VERSION "created by canmatrix"

NS_ :

BS_:

BU_: User ADM_PC_LL25 ADM_PC_BC25 ADM_PC_BP25 ADM_PC_BI25

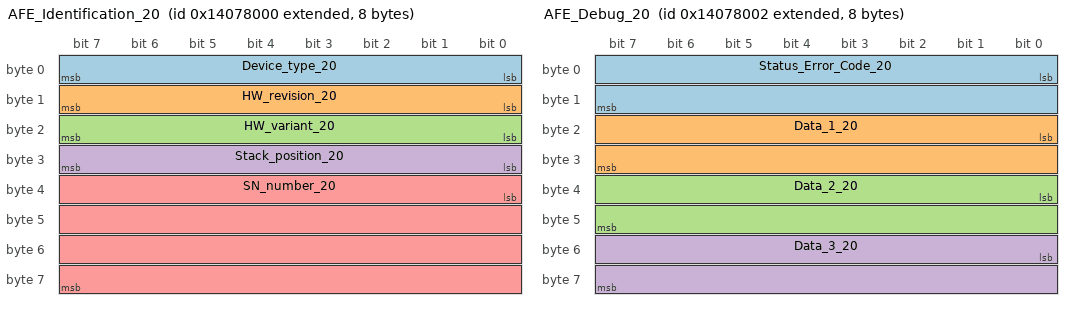
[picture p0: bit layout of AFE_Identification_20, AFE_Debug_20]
BO_ 2483519488 AFE_Identification_20: 8 ADM_PC_BP25
 SG_ Device_type_20 : 0|8@1+ (1,0) [0|255] "" Vector__XXX
 SG_ HW_revision_20 : 8|8@1+ (1,0) [0|255] "" Vector__XXX
 SG_ HW_variant_20 : 16|8@1+ (1,0) [0|255] "" Vector__XXX
 SG_ Stack_position_20 : 24|8@1+ (1,0) [0|255] "" Vector__XXX
 SG_ SN_number_20 : 32|32@1+ (1,0) [0|4294967295] "" Vector__XXX

BO_ 2483519489 AFE_FwInfo_20: 8 ADM_PC_BP25
 SG_ FW_info_mux_20 M : 56|8@1+ (1,0) [0|255] "" Vector__XXX
 SG_ FW_revision_0_20 m0 : 0|8@1+ (1,0) [0|255] "" Vector__XXX
 SG_ FW_revision_1_20 m0 : 8|8@1+ (1,0) [0|255] "" Vector__XXX
 SG_ FW_revision_2_20 m0 : 16|8@1+ (1,0) [0|255] "" Vector__XXX
 SG_ FW_revision_3_20 m0 : 24|8@1+ (1,0) [0|255] "" Vector__XXX
 SG_ FW_revision_4_20 m0 : 32|8@1+ (1,0) [0|255] "" Vector__XXX
 SG_ FW_revision_5_20 m0 : 40|8@1+ (1,0) [0|255] "" Vector__XXX
 SG_ FW_revision_6_20 m0 : 48|8@1+ (1,0) [0|255] "" Vector__XXX
 SG_ FW_revision_7_20 m1 : 0|8@1+ (1,0) [0|255] "" Vector__XXX
 SG_ FW_revision_8_20 m1 : 8|8@1+ (1,0) [0|255] "" Vector__XXX
 SG_ FW_revision_9_20 m1 : 16|8@1+ (1,0) [0|255] "" Vector__XXX
 SG_ FW_revision_10_20 m1 : 24|8@1+ (1,0) [0|255] "" Vector__XXX
 SG_ FW_revision_11_20 m1 : 32|8@1+ (1,0) [0|255] "" Vector__XXX
 SG_ FW_revision_12_20 m1 : 40|8@1+ (1,0) [0|255] "" Vector__XXX
 SG_ FW_revision_13_20 m1 : 48|8@1+ (1,0) [0|255] "" Vector__XXX
 SG_ FW_datecode_0_20 m2 : 0|8@1+ (1,0) [0|255] "" Vector__XXX
 SG_ FW_datecode_1_20 m2 : 8|8@1+ (1,0) [0|255] "" Vector__XXX
 SG_ FW_datecode_2_20 m2 : 16|8@1+ (1,0) [0|255] "" Vector__XXX
 SG_ FW_datecode_3_20 m2 : 24|8@1+ (1,0) [0|255] "" Vector__XXX
 SG_ FW_datecode_4_20 m2 : 32|8@1+ (1,0) [0|255] "" Vector__XXX
 SG_ FW_datecode_5_20 m2 : 40|8@1+ (1,0) [0|255] "" Vector__XXX
 SG_ FW_datecode_6_20 m2 : 48|8@1+ (1,0) [0|255] "" Vector__XXX
 SG_ FW_datecode_7_20 m3 : 0|8@1+ (1,0) [0|255] "" Vector__XXX
 SG_ FW_datecode_8_20 m3 : 8|8@1+ (1,0) [0|255] "" Vector__XXX
 SG_ FW_datecode_9_20 m3 : 16|8@1+ (1,0) [0|255] "" Vector__XXX
 SG_ FW_datecode_10_20 m3 : 24|8@1+ (1,0) [0|255] "" Vector__XXX
 SG_ FW_datecode_11_20 m3 : 32|8@1+ (1,0) [0|255] "" Vector__XXX
 SG_ FW_datecode_12_20 m3 : 40|8@1+ (1,0) [0|255] "" Vector__XXX
 SG_ FW_datecode_13_20 m3 : 48|8@1+ (1,0) [0|255] "" Vector__XXX

BO_ 2483519501 _AFE_Boot_FwInfo_20: 8 ADM_PC_BP25
 SG_ Boot_FW_info_mux_20 M : 56|8@1+ (1,0) [0|255] "" Vector__XXX
 SG_ FW_revision_0_20 m0 : 0|8@1+ (1,0) [0|255] "" Vector__XXX
 SG_ FW_revision_1_20 m0 : 8|8@1+ (1,0) [0|255] "" Vector__XXX
 SG_ FW_revision_2_20 m0 : 16|8@1+ (1,0) [0|255] "" Vector__XXX
 SG_ FW_revision_3_20 m0 : 24|8@1+ (1,0) [0|255] "" Vector__XXX
 SG_ FW_revision_4_20 m0 : 32|8@1+ (1,0) [0|255] "" Vector__XXX
 SG_ FW_revision_5_20 m0 : 40|8@1+ (1,0) [0|255] "" Vector__XXX
 SG_ FW_revision_6_20 m0 : 48|8@1+ (1,0) [0|255] "" Vector__XXX
 SG_ FW_revision_7_20 m1 : 0|8@1+ (1,0) [0|255] "" Vector__XXX
 SG_ FW_revision_8_20 m1 : 8|8@1+ (1,0) [0|255] "" Vector__XXX
 SG_ FW_revision_9_20 m1 : 16|8@1+ (1,0) [0|255] "" Vector__XXX
 SG_ FW_revision_10_20 m1 : 24|8@1+ (1,0) [0|255] "" Vector__XXX
 SG_ FW_revision_11_20 m1 : 32|8@1+ (1,0) [0|255] "" Vector__XXX
 SG_ FW_revision_12_20 m1 : 40|8@1+ (1,0) [0|255] "" Vector__XXX
 SG_ FW_revision_13_20 m1 : 48|8@1+ (1,0) [0|255] "" Vector__XXX
 SG_ FW_datecode_0_20 m2 : 0|8@1+ (1,0) [0|255] "" Vector__XXX
 SG_ FW_datecode_1_20 m2 : 8|8@1+ (1,0) [0|255] "" Vector__XXX
 SG_ FW_datecode_2_20 m2 : 16|8@1+ (1,0) [0|255] "" Vector__XXX
 SG_ FW_datecode_3_20 m2 : 24|8@1+ (1,0) [0|255] "" Vector__XXX
 SG_ FW_datecode_4_20 m2 : 32|8@1+ (1,0) [0|255] "" Vector__XXX
 SG_ FW_datecode_5_20 m2 : 40|8@1+ (1,0) [0|255] "" Vector__XXX
 SG_ FW_datecode_6_20 m2 : 48|8@1+ (1,0) [0|255] "" Vector__XXX
 SG_ FW_datecode_7_20 m3 : 0|8@1+ (1,0) [0|255] "" Vector__XXX
 SG_ FW_datecode_8_20 m3 : 8|8@1+ (1,0) [0|255] "" Vector__XXX
 SG_ FW_datecode_9_20 m3 : 16|8@1+ (1,0) [0|255] "" Vector__XXX
 SG_ FW_datecode_10_20 m3 : 24|8@1+ (1,0) [0|255] "" Vector__XXX
 SG_ FW_datecode_11_20 m3 : 32|8@1+ (1,0) [0|255] "" Vector__XXX
 SG_ FW_datecode_12_20 m3 : 40|8@1+ (1,0) [0|255] "" Vector__XXX
 SG_ FW_datecode_13_20 m3 : 48|8@1+ (1,0) [0|255] "" Vector__XXX

BO_ 2483519490 AFE_Debug_20: 8 ADM_PC_BP25
 SG_ Status_Error_Code_20 : 0|16@1+ (1,0) [0|65535] "" Vector__XXX
 SG_ Data_1_20 : 16|16@1+ (1,0) [0|65535] "" Vector__XXX
 SG_ Data_2_20 : 32|16@1+ (1,0) [0|65535] "" Vector__XXX
 SG_ Data_3_20 : 48|16@1+ (1,0) [0|65535] "" Vector__XXX

BO_ 2483519495 AFE_Status_20: 8 ADM_PC_BP25
 SG_ Running_20 : 0|1@1+ (1,0) [0|1] "" Vector__XXX
 SG_ PWM_20 : 1|1@1+ (1,0) [0|1] "" Vector__XXX
 SG_ Current_dc_loop_mode_20 : 2|1@1+ (1,0) [0|1] "" Vector__XXX
 SG_ Current_ac_loop_mode_20 : 3|1@1+ (1,0) [0|1] "" Vector__XXX
 SG_ Buck_20 : 5|1@1+ (1,0) [0|1] "" Vector__XXX
 SG_ Boost_20 : 6|1@1+ (1,0) [0|1] "" Vector__XXX
 SG_ Precharge_dc_buck_mode_20 : 7|1@1+ (1,0) [0|1] "" Vector__XXX
 SG_ Precharge_dc_boost_mode_20 : 8|1@1+ (1,0) [0|1] "" Vector__XXX
 SG_ Rectifier_3ph_20 : 9|1@1+ (1,0) [0|1] "" Vector__XXX
 SG_ Stack_mode_20 : 10|1@1+ (1,0) [0|1] "" Vector__XXX
 SG_ Master_20 : 11|1@1+ (1,0) [0|1] "" Vector__XXX
 SG_ Slave_20 : 12|1@1+ (1,0) [0|1] "" Vector__XXX
 SG_ Inverter_1ph_20 : 13|1@1+ (1,0) [0|1] "" Vector__XXX
 SG_ Boost_Neutral_20 : 14|1@1+ (1,0) [0|1] "" Vector__XXX
 SG_ Rectifier_1ph_20 : 15|1@1+ (1,0) [0|1] "" Vector__XXX
 SG_ Inverter_3ph_20 : 16|1@1+ (1,0) [0|1] "" Vector__XXX
 SG_ Ready_20 : 17|1@1+ (1,0) [0|1] "" Vector__XXX
 SG_ Inverter_1ph_Sync_20 : 18|1@1+ (1,0) [0|1] "" Vector__XXX
 SG_ Neutral_20 : 19|1@1+ (1,0) [0|1] "" Vector__XXX
 SG_ Rectifier_1ph_Buck_20 : 20|1@1+ (1,0) [0|1] "" Vector__XXX
 SG_ Inverter_1ph_Boost_20 : 21|1@1+ (1,0) [0|1] "" Vector__XXX
 SG_ Rectifier_distributed_20 : 22|1@1+ (1,0) [0|1] "" Vector__XXX
 SG_ MPPT_buck_20 : 23|1@1+ (1,0) [0|1] "" Vector__XXX
 SG_ MPPT_boost_20 : 24|1@1+ (1,0) [0|1] "" Vector__XXX
 SG_ Buck_2p_float_20 : 25|1@1+ (1,0) [0|1] "" Vector__XXX
 SG_ Inverter_1ph_Distributed_20 : 26|1@1+ (1,0) [0|1] "" Vector__XXX

BO_ 2483519494 AFE_Faults_20: 3 ADM_PC_BP25
 SG_ Protection_trip_internal_20 : 0|1@1+ (1,0) [0|1] "" Vector__XXX
 SG_ Protection_trip_external_20 : 1|1@1+ (1,0) [0|1] "" Vector__XXX
 SG_ Phase_U_overcurrent_20 : 2|1@1+ (1,0) [0|1] "" Vector__XXX
 SG_ Phase_U_overvoltage_20 : 3|1@1+ (1,0) [0|1] "" Vector__XXX
 SG_ Phase_U_undervoltage_20 : 4|1@1+ (1,0) [0|1] "" Vector__XXX
 SG_ Phase_V_overvoltage_20 : 5|1@1+ (1,0) [0|1] "" Vector__XXX
 SG_ Phase_V_undervoltage_20 : 6|1@1+ (1,0) [0|1] "" Vector__XXX
 SG_ Phase_V_overcurrent_20 : 7|1@1+ (1,0) [0|1] "" Vector__XXX
 SG_ Phase_W_overvoltage_20 : 8|1@1+ (1,0) [0|1] "" Vector__XXX
 SG_ Phase_W_undervoltage_20 : 9|1@1+ (1,0) [0|1] "" Vector__XXX
 SG_ Phase_W_overcurrent_20 : 10|1@1+ (1,0) [0|1] "" Vector__XXX
 SG_ DC_undervoltage_20 : 11|1@1+ (1,0) [0|1] "" Vector__XXX
 SG_ DC_overvoltage_20 : 12|1@1+ (1,0) [0|1] "" Vector__XXX
 SG_ MOSFET_overtemperature_20 : 13|1@1+ (1,0) [0|1] "" Vector__XXX
 SG_ Inductor_overtemperature_20 : 14|1@1+ (1,0) [0|1] "" Vector__XXX
 SG_ Keep_Alive_not_served_20 : 15|1@1+ (1,0) [0|1] "" Vector__XXX
 SG_ PLL_not_locked_20 : 16|1@1+ (1,0) [0|1] "" Vector__XXX
 SG_ NFO_20 : 20|1@1+ (1,0) [0|1] "" Vector__XXX
 SG_ Measurement_system_failure_20 : 21|1@1+ (1,0) [0|1] "" Vector__XXX
 SG_ EEPROM_failure_20 : 22|1@1+ (1,0) [0|1] "" Vector__XXX
 SG_ System_20 : 23|1@1+ (1,0) [0|1] "" Vector__XXX

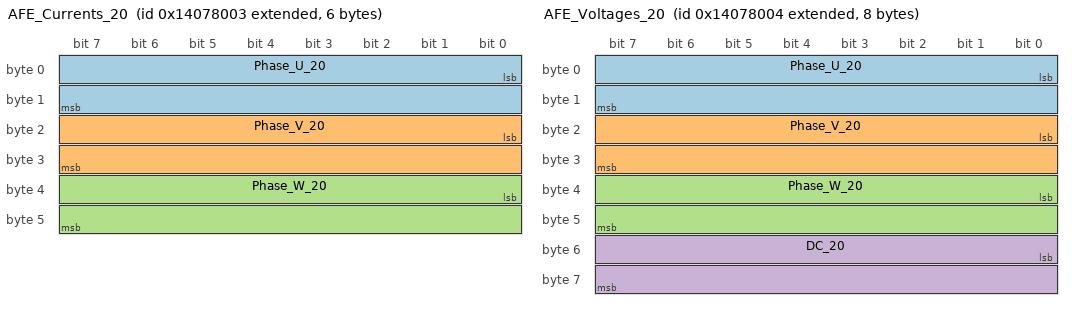
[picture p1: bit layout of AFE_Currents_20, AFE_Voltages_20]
BO_ 2483519491 AFE_Currents_20: 6 ADM_PC_BP25
 SG_ Phase_U_20 : 0|16@1- (0.01,0) [-327.68|327.67] "A" Vector__XXX
 SG_ Phase_V_20 : 16|16@1- (0.01,0) [-327.68|327.67] "A" Vector__XXX
 SG_ Phase_W_20 : 32|16@1- (0.01,0) [-327.68|327.67] "A" Vector__XXX

BO_ 2483519504 AFE_DC_Bus_current_20: 2 ADM_PC_BP25
 SG_ Bus_current_20 : 0|16@1- (0.01,0) [-327.68|327.67] "A" Vector__XXX

BO_ 2483519502 _AFE_Broadcast_20: 8 ADM_PC_BP25
 SG_ Diagnostics_Index_20 M : 56|8@1+ (1,0) [0|255] "" Vector__XXX
 SG_ Phase_U_20 m1 : 8|16@1- (0.01,0) [-327.68|327.67] "A" ADM_PC_BP25
 SG_ Phase_V_20 m1 : 24|16@1- (0.01,0) [-327.68|327.67] "A" ADM_PC_BP25
 SG_ Phase_W_20 m1 : 40|16@1- (0.01,0) [-327.68|327.67] "A" ADM_PC_BP25
 SG_ Stack_position_20 : 0|5@1+ (1,0) [0|31] "" ADM_PC_BP25
 SG_ Group_ID_20 : 5|3@1+ (1,0) [0|7] "" ADM_PC_BP25

BO_ 2483519492 AFE_Voltages_20: 8 ADM_PC_BP25
 SG_ Phase_U_20 : 0|16@1- (0.1,0) [-3276.8|3276.7] "V" Vector__XXX
 SG_ Phase_V_20 : 16|16@1- (0.1,0) [-3276.8|3276.7] "V" Vector__XXX
 SG_ Phase_W_20 : 32|16@1- (0.1,0) [-3276.8|3276.7] "V" Vector__XXX
 SG_ DC_20 : 48|16@1- (0.1,0) [-3276.8|3276.7] "V" Vector__XXX

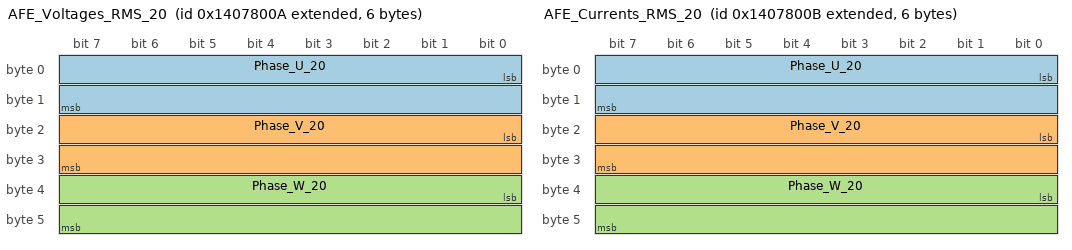
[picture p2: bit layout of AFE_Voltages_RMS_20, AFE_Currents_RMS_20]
BO_ 2483519498 AFE_Voltages_RMS_20: 6 ADM_PC_BP25
 SG_ Phase_U_20 : 0|16@1+ (0.1,0) [0|6553.5] "V" Vector__XXX
 SG_ Phase_V_20 : 16|16@1+ (0.1,0) [0|6553.5] "V" Vector__XXX
 SG_ Phase_W_20 : 32|16@1+ (0.1,0) [0|6553.5] "V" Vector__XXX

BO_ 2483519499 AFE_Currents_RMS_20: 6 ADM_PC_BP25
 SG_ Phase_U_20 : 0|16@1+ (0.01,0) [0.00|655.35] "A" Vector__XXX
 SG_ Phase_V_20 : 16|16@1+ (0.01,0) [0.00|655.35] "A" Vector__XXX
 SG_ Phase_W_20 : 32|16@1+ (0.01,0) [0.00|655.35] "A" Vector__XXX

BO_ 2483519500 AFE_Mains_20: 4 ADM_PC_BP25
 SG_ Frequency_20 : 0|16@1+ (0.01,0) [0.00|655.35] "Hz" Vector__XXX
 SG_ Phase_20 : 16|16@1- (0.1,0) [-3276.8|3276.7] "Deg." Vector__XXX

BO_ 2483519493 AFE_Temperatures_20: 4 ADM_PC_BP25
 SG_ Temp_Bridge_20 : 0|16@1- (0.01,0) [-327.68|327.67] "°C" Vector__XXX
 SG_ Temp_Inductors_20 : 16|16@1- (0.01,0) [-327.68|327.67] "°C" Vector__XXX

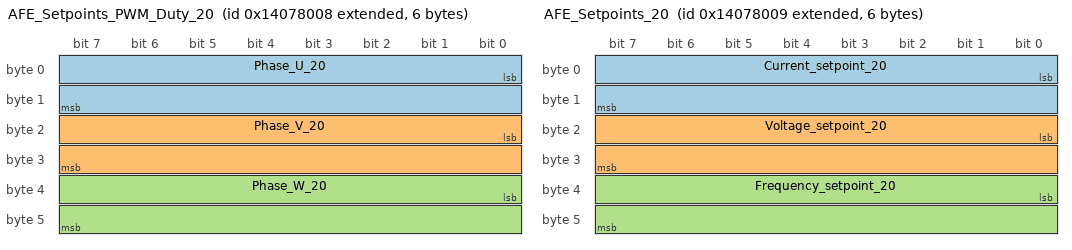
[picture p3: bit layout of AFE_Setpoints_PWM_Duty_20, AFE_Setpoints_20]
BO_ 2483519496 AFE_Setpoints_PWM_Duty_20: 6 ADM_PC_BP25
 SG_ Phase_U_20 : 0|16@1+ (0.001525902,0) [0E-009|99.999987570] "%" Vector__XXX
 SG_ Phase_V_20 : 16|16@1+ (0.001525902,0) [0E-009|99.999987570] "%" Vector__XXX
 SG_ Phase_W_20 : 32|16@1+ (0.001525902,0) [0E-009|99.999987570] "%" Vector__XXX

BO_ 2483519497 AFE_Setpoints_20: 6 ADM_PC_BP25
 SG_ Current_setpoint_20 : 0|16@1- (0.01,0) [-327.68|327.67] "A" Vector__XXX
 SG_ Voltage_setpoint_20 : 16|16@1+ (0.1,0) [0|6553.5] "V" Vector__XXX
 SG_ Frequency_setpoint_20 : 32|16@1+ (0.01,0) [0.00|655.35] "Hz" Vector__XXX

BO_ 2483486816 AFE_Keep_Alive_20: 1 User
 SG_ Keep_Alive_Enable_20 : 0|1@1+ (1,0) [0|1] "" ADM_PC_BP25

BO_ 2483486784 AFE_Mode_Control_20: 8 User
 SG_ Converter_ON_20 : 0|1@1+ (1,0) [0|1] "" ADM_PC_BP25
 SG_ PWM_ON_20 : 1|1@1+ (1,0) [0|1] "" ADM_PC_BP25
 SG_ DC_Current_feedback_ON_20 : 2|1@1+ (1,0) [0|1] "" ADM_PC_BP25
 SG_ AC_Current_feedback_ON_20 : 3|1@1+ (1,0) [0|1] "" ADM_PC_BP25
 SG_ Buck_ON_20 : 5|1@1+ (1,0) [0|1] "" ADM_PC_BP25
 SG_ Boost_ON_20 : 6|1@1+ (1,0) [0|1] "" ADM_PC_BP25
 SG_ Rectifier_3ph_ON_20 : 9|1@1+ (1,0) [0|1] "" ADM_PC_BP25
 SG_ Inverter_1ph_ON_20 : 10|1@1+ (1,0) [0|1] "" ADM_PC_BP25
 SG_ Rectifier_1ph_ON_20 : 11|1@1+ (1,0) [0|1] "" ADM_PC_BP25
 SG_ Boost_Neutral_ON_20 : 12|1@1+ (1,0) [0|1] "" ADM_PC_BP25
 SG_ Inverter_3ph_ON_20 : 13|1@1+ (1,0) [0|1] "" ADM_PC_BP25
 SG_ Inverter_1ph_Sync_ON_20 : 14|1@1+ (1,0) [0|1] "" ADM_PC_BP25
 SG_ Neutral_ON_20 : 15|1@1+ (1,0) [0|1] "" ADM_PC_BP25
 SG_ Rectifier_1ph_Buck_ON_20 : 16|1@1+ (1,0) [0|1] "" ADM_PC_BP25
 SG_ Inverter_1ph_Boost_ON_20 : 17|1@1+ (1,0) [0|1] "" ADM_PC_BP25
 SG_ Rectifier_Distributed_ON_20 : 18|1@1+ (1,0) [0|1] "" ADM_PC_BP25
 SG_ MPPT_buck_ON_20 : 19|1@1+ (1,0) [0|1] "" ADM_PC_BP25
 SG_ MPPT_boost_ON_20 : 20|1@1+ (1,0) [0|1] "" ADM_PC_BP25
 SG_ Buck_2p_float_ON_20 : 21|1@1+ (1,0) [0|1] "" ADM_PC_BP25
 SG_ Inverter_1ph_Distributed_ON_20 : 22|1@1+ (1,0) [0|1] "" ADM_PC_BP25

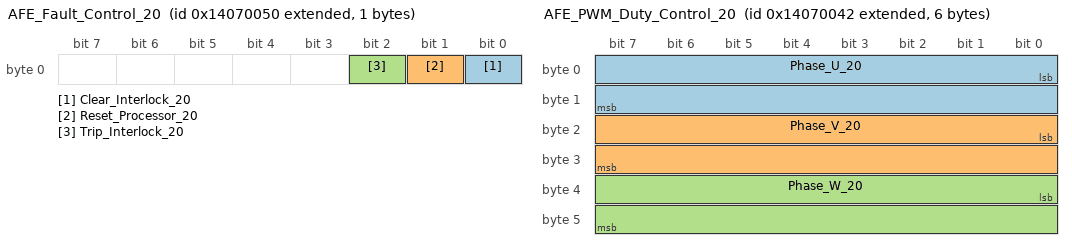
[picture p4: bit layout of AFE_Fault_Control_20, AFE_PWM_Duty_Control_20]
BO_ 2483486800 AFE_Fault_Control_20: 1 User
 SG_ Clear_Interlock_20 : 0|1@1+ (1,0) [0|1] "" ADM_PC_BP25
 SG_ Reset_Processor_20 : 1|1@1+ (1,0) [0|1] "" ADM_PC_BP25
 SG_ Trip_Interlock_20 : 2|1@1+ (1,0) [0|1] "" ADM_PC_BP25

BO_ 2483486785 AFE_Reactive_Current_Setpoint_Co: 2 User
 SG_ Reactive_current_setpoint_20 : 0|16@1- (0.01,0) [-150|150] "A" ADM_PC_BP25

BO_ 2483486786 AFE_PWM_Duty_Control_20: 6 User
 SG_ Phase_U_20 : 0|16@1+ (0.001525902,0) [0E-009|99.999987570] "%" ADM_PC_BP25
 SG_ Phase_V_20 : 16|16@1+ (0.001525902,0) [0E-009|99.999987570] "%" ADM_PC_BP25
 SG_ Phase_W_20 : 32|16@1+ (0.001525902,0) [0E-009|99.999987570] "%" ADM_PC_BP25

BO_ 2483486787 AFE_Current_Setpoint_Control_20: 2 User
 SG_ Current_setpoint_20 : 0|16@1- (0.01,0) [-150|150] "A" ADM_PC_BP25

BO_ 2483486788 AFE_Voltage_Setpoint_Control_20: 2 User
 SG_ Voltage_setpoint_20 : 0|16@1+ (0.1,0) [0|1500] "V" ADM_PC_BP25

BO_ 2483486792 AFE_Frequency_Setpoint_Control_2: 2 User
 SG_ Frequency_setpoint_20 : 0|16@1+ (0.01,0) [40|70] "Hz" ADM_PC_BP25

BO_ 2483486793 AFE_Phase_Setpoint_Control_20: 2 User
 SG_ Phase_setpoint_20 : 0|16@1+ (1,0) [0|360] "deg" ADM_PC_BP25

BO_ 2483486832 AFE_Rectifier_Setpoint_Control_2: 8 User
 SG_ Voltage_setpoint_2_20 : 0|16@1+ (0.1,0) [0|1500] "V" ADM_PC_BP25
 SG_ Current_setpoint_2_20 : 16|16@1- (0.01,0) [-150|150] "A" ADM_PC_BP25

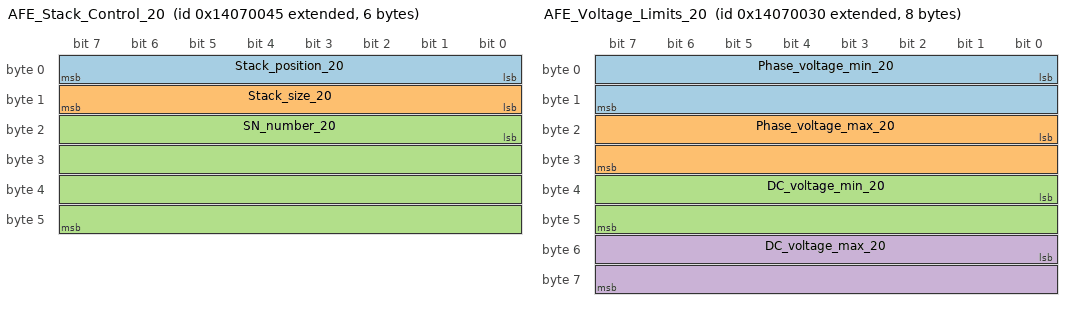
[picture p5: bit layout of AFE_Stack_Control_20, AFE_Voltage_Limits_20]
BO_ 2483486789 AFE_Stack_Control_20: 6 User
 SG_ Stack_position_20 : 0|8@1+ (1,0) [0|255] "" ADM_PC_BP25
 SG_ Stack_size_20 : 8|8@1+ (1,0) [0|255] "" ADM_PC_BP25
 SG_ SN_number_20 : 16|32@1+ (1,0) [0|4294967295] "" ADM_PC_BP25

BO_ 2483486768 AFE_Voltage_Limits_20: 8 User
 SG_ Phase_voltage_min_20 : 0|16@1- (0.1,0) [0|3276.7] "V" ADM_PC_BP25
 SG_ Phase_voltage_max_20 : 16|16@1- (0.1,0) [-3276.8|850] "V" ADM_PC_BP25
 SG_ DC_voltage_min_20 : 32|16@1- (0.1,0) [0|3276.7] "V" ADM_PC_BP25
 SG_ DC_voltage_max_20 : 48|16@1- (0.1,0) [-3276.8|850] "V" ADM_PC_BP25

BO_ 2483486769 AFE_Current_Limits_20: 4 User
 SG_ Phase_current_min_20 : 0|16@1- (0.01,0) [-60|60] "A" ADM_PC_BP25
 SG_ Phase_current_max_20 : 16|16@1- (0.01,0) [-60|60] "A" ADM_PC_BP25

BO_ 2483486796 AFE_Group_Control_20: 1 User
 SG_ Group_ID_20 : 0|8@1+ (1,0) [0|255] "" ADM_PC_BP25

BO_ 2483519503 AFE_Group_Info_20: 1 ADM_PC_BP25
 SG_ Group_ID_20 : 0|8@1+ (1,0) [0|255] "" Vector__XXX

BO_ 2483486817 AFE_System_Flags_Control_20: 8 User
 SG_ Factory_mode_20 : 0|1@1+ (1,0) [0|1] "" ADM_PC_BP25
 SG_ Silent_CAN_mode_20 : 1|1@1+ (1,0) [0|1] "" ADM_PC_BP25

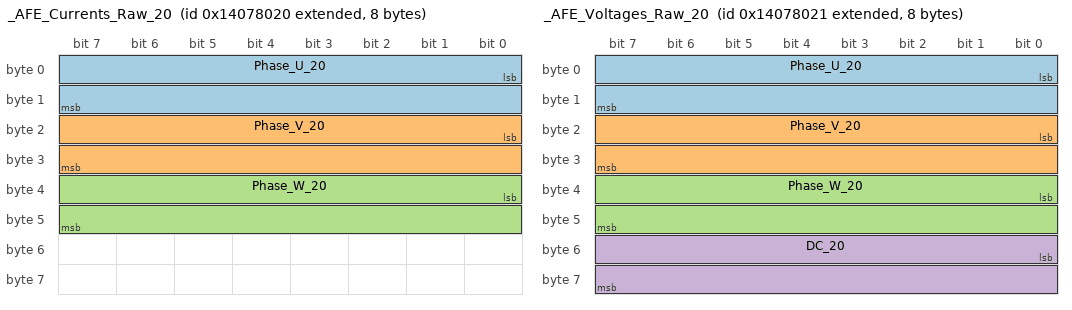
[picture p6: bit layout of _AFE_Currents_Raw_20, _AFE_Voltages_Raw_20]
BO_ 2483519520 _AFE_Currents_Raw_20: 8 ADM_PC_BP25
 SG_ Phase_U_20 : 0|16@1- (1,0) [-32768|32767] "" Vector__XXX
 SG_ Phase_V_20 : 16|16@1- (1,0) [-32768|32767] "" Vector__XXX
 SG_ Phase_W_20 : 32|16@1- (1,0) [-32768|32767] "" Vector__XXX

BO_ 2483519521 _AFE_Voltages_Raw_20: 8 ADM_PC_BP25
 SG_ Phase_U_20 : 0|16@1- (1,0) [-32768|32767] "" Vector__XXX
 SG_ Phase_V_20 : 16|16@1- (1,0) [-32768|32767] "" Vector__XXX
 SG_ Phase_W_20 : 32|16@1- (1,0) [-32768|32767] "" Vector__XXX
 SG_ DC_20 : 48|16@1- (1,0) [-32768|32767] "" Vector__XXX

BO_ 2483486794 _AFE_ADC_Calibration_Mode_20: 1 User
 SG_ Calibration_Index_20 M : 2|5@1+ (1,0) [0|31] "" Vector__XXX
 SG_ Current_U_20 m1 : 0|2@1+ (1,0) [0|3] "" ADM_PC_BP25
 SG_ Current_V_20 m2 : 0|2@1+ (1,0) [0|3] "" ADM_PC_BP25
 SG_ Current_W_20 m3 : 0|2@1+ (1,0) [0|3] "" ADM_PC_BP25
 SG_ Voltage_U_20 m4 : 0|2@1+ (1,0) [0|3] "" ADM_PC_BP25
 SG_ Voltage_V_20 m5 : 0|2@1+ (1,0) [0|3] "" ADM_PC_BP25
 SG_ Voltage_W_20 m6 : 0|2@1+ (1,0) [0|3] "" ADM_PC_BP25
 SG_ Voltage_DC_20 m7 : 0|2@1+ (1,0) [0|3] "" ADM_PC_BP25
 SG_ start_20 : 7|1@1+ (1,0) [0|1] "" ADM_PC_BP25

BO_ 2483486795 _AFE_ADC_Calibration_Setpoint_20: 3 User
 SG_ Calibration_Index_20 M : 16|5@1+ (1,0) [0|31] "" Vector__XXX
 SG_ Current_U_20 m1 : 0|16@1- (0.01,0) [-100|100] "A" ADM_PC_BP25
 SG_ Current_V_20 m2 : 0|16@1- (0.01,0) [-100|100] "A" ADM_PC_BP25
 SG_ Current_W_20 m3 : 0|16@1- (0.01,0) [-100|100] "A" ADM_PC_BP25
 SG_ Voltage_U_20 m4 : 0|16@1+ (0.1,0) [0|1500] "V" ADM_PC_BP25
 SG_ Voltage_V_20 m5 : 0|16@1+ (0.1,0) [0|1500] "V" ADM_PC_BP25
 SG_ Voltage_W_20 m6 : 0|16@1+ (0.1,0) [0|1500] "V" ADM_PC_BP25
 SG_ Voltage_DC_20 m7 : 0|16@1+ (0.1,0) [0|1500] "V" ADM_PC_BP25
 SG_ point_20 : 21|3@1+ (1,0) [0|7] "" ADM_PC_BP25

BO_ 2483486790 _AFE_Calibration_Offset_Update_2: 6 User
 SG_ Calibration_Index_20 M : 16|16@1+ (1,0) [0|65535] "" Vector__XXX
 SG_ Current_U_20 m0 : 0|16@1- (1,0) [-32768|32767] "ADC Counts" ADM_PC_BP25
 SG_ Current_V_20 m1 : 0|16@1- (1,0) [-32768|32767] "ADC Counts" ADM_PC_BP25
 SG_ Current_W_20 m2 : 0|16@1- (1,0) [-32768|32767] "ADC Counts" ADM_PC_BP25
 SG_ Voltage_U_20 m3 : 0|16@1- (1,0) [-32768|32767] "ADC Counts" ADM_PC_BP25
 SG_ Voltage_V_20 m4 : 0|16@1- (1,0) [-32768|32767] "ADC Counts" ADM_PC_BP25
 SG_ Voltage_W_20 m5 : 0|16@1- (1,0) [-32768|32767] "ADC Counts" ADM_PC_BP25
 SG_ Voltage_DC_20 m6 : 0|16@1- (1,0) [-32768|32767] "ADC Counts" ADM_PC_BP25
 SG_ CRC_20 : 32|16@1+ (1,0) [0|65535] "-" ADM_PC_BP25

BO_ 2483486791 _AFE_Calibration_Scale_Update_20: 6 User
 SG_ Calibration_Index_20 M : 16|16@1+ (1,0) [0|65535] "" Vector__XXX
 SG_ Current_U_20 m0 : 0|16@1- (0.0000152587890625,0) [-0.5000000000000000|0.4999847412109375] "scale = 1.0 + value" ADM_PC_BP25
 SG_ Current_V_20 m1 : 0|16@1- (0.0000152587890625,0) [-0.5000000000000000|0.4999847412109375] "scale = 1.0 + value" ADM_PC_BP25
 SG_ Current_W_20 m2 : 0|16@1- (0.0000152587890625,0) [-0.5000000000000000|0.4999847412109375] "scale = 1.0 + value" ADM_PC_BP25
 SG_ Voltage_U_20 m3 : 0|16@1- (0.0000152587890625,0) [-0.5000000000000000|0.4999847412109375] "scale = 1.0 + value" ADM_PC_BP25
 SG_ Voltage_V_20 m4 : 0|16@1- (0.0000152587890625,0) [-0.5000000000000000|0.4999847412109375] "scale = 1.0 + value" ADM_PC_BP25
 SG_ Voltage_W_20 m5 : 0|16@1- (0.0000152587890625,0) [-0.5000000000000000|0.4999847412109375] "scale = 1.0 + value" ADM_PC_BP25
 SG_ Voltage_DC_20 m6 : 0|16@1- (0.0000152587890625,0) [-0.5000000000000000|0.4999847412109375] "scale = 1.0 + value" ADM_PC_BP25
 SG_ CRC_20 : 32|16@1+ (1,0) [0|65535] "-" ADM_PC_BP25

BO_ 2483519569 _AFE_Calibration_Adc_Scale_20: 6 ADM_PC_BP25
 SG_ Adc_Index_20 M : 32|16@1+ (1,0) [0|65535] "" Vector__XXX
 SG_ Current_U_20 m0 : 0|32@1+ (1,0) [0|4294967295] "1 / adc_bins" User
 SG_ Current_V_20 m1 : 0|32@1+ (1,0) [0|4294967295] "1 / adc_bins" User
 SG_ Current_W_20 m2 : 0|32@1+ (1,0) [0|4294967295] "1 / adc_bins" User
 SG_ Voltage_U_20 m3 : 0|32@1+ (1,0) [0|4294967295] "1 / adc_bins" User
 SG_ Voltage_V_20 m4 : 0|32@1+ (1,0) [0|4294967295] "1 / adc_bins" User
 SG_ Voltage_W_20 m5 : 0|32@1+ (1,0) [0|4294967295] "1 / adc_bins" User
 SG_ Voltage_DC_20 m6 : 0|32@1+ (1,0) [0|4294967295] "1 / adc_bins" User

BO_ 2483519570 _AFE_Calibration_Adc_Fs_20: 6 ADM_PC_BP25
 SG_ Adc_Index_20 M : 32|16@1+ (1,0) [0|65535] "" Vector__XXX
 SG_ Current_U_20 m0 : 0|32@1+ (1,0) [0|4294967295] "Fullscale" User
 SG_ Current_V_20 m1 : 0|32@1+ (1,0) [0|4294967295] "Fullscale" User
 SG_ Current_W_20 m2 : 0|32@1+ (1,0) [0|4294967295] "Fullscale" User
 SG_ Voltage_U_20 m3 : 0|32@1+ (1,0) [0|4294967295] "Fullscale" User
 SG_ Voltage_V_20 m4 : 0|32@1+ (1,0) [0|4294967295] "Fullscale" User
 SG_ Voltage_W_20 m5 : 0|32@1+ (1,0) [0|4294967295] "Fullscale" User
 SG_ Voltage_DC_20 m6 : 0|32@1+ (1,0) [0|4294967295] "Fullscale" User

BO_ 2483519571 _AFE_Calibration_Adc_Offset_20: 4 ADM_PC_BP25
 SG_ Adc_Index_20 M : 16|16@1+ (1,0) [0|65535] "" Vector__XXX
 SG_ Current_U_20 m0 : 0|16@1- (1,0) [-32768|32767] "-" User
 SG_ Current_V_20 m1 : 0|16@1- (1,0) [-32768|32767] "-" User
 SG_ Current_W_20 m2 : 0|16@1- (1,0) [-32768|32767] "-" User
 SG_ Voltage_U_20 m3 : 0|16@1- (1,0) [-32768|32767] "-" User
 SG_ Voltage_V_20 m4 : 0|16@1- (1,0) [-32768|32767] "-" User
 SG_ Voltage_W_20 m5 : 0|16@1- (1,0) [-32768|32767] "-" User
 SG_ Voltage_DC_20 m6 : 0|16@1- (1,0) [-32768|32767] "-" User

BO_ 2483519572 _AFE_Calibration_Adc_Gain_20: 4 ADM_PC_BP25
 SG_ Adc_Index_20 M : 16|16@1+ (1,0) [0|65535] "" Vector__XXX
 SG_ Current_U_20 m0 : 0|16@1- (1,0) [-32768|32767] "-" User
 SG_ Current_V_20 m1 : 0|16@1- (1,0) [-32768|32767] "-" User
 SG_ Current_W_20 m2 : 0|16@1- (1,0) [-32768|32767] "-" User
 SG_ Voltage_U_20 m3 : 0|16@1- (1,0) [-32768|32767] "-" User
 SG_ Voltage_V_20 m4 : 0|16@1- (1,0) [-32768|32767] "-" User
 SG_ Voltage_W_20 m5 : 0|16@1- (1,0) [-32768|32767] "-" User
 SG_ Voltage_DC_20 m6 : 0|16@1- (1,0) [-32768|32767] "-" User

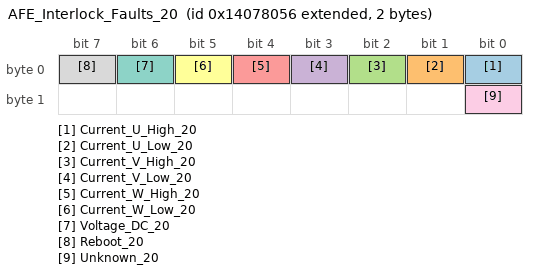
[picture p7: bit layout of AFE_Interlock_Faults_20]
BO_ 2483519574 AFE_Interlock_Faults_20: 2 ADM_PC_BP25
 SG_ Current_U_High_20 : 0|1@1+ (1,0) [0|1] "" Vector__XXX
 SG_ Current_U_Low_20 : 1|1@1+ (1,0) [0|1] "" Vector__XXX
 SG_ Current_V_High_20 : 2|1@1+ (1,0) [0|1] "" Vector__XXX
 SG_ Current_V_Low_20 : 3|1@1+ (1,0) [0|1] "" Vector__XXX
 SG_ Current_W_High_20 : 4|1@1+ (1,0) [0|1] "" Vector__XXX
 SG_ Current_W_Low_20 : 5|1@1+ (1,0) [0|1] "" Vector__XXX
 SG_ Voltage_DC_20 : 6|1@1+ (1,0) [0|1] "" Vector__XXX
 SG_ Reboot_20 : 7|1@1+ (1,0) [0|1] "" Vector__XXX
 SG_ Unknown_20 : 8|1@1+ (1,0) [0|1] "" Vector__XXX

BO_TX_BU_ 2483486784 : User,ADM_PC_LL25,ADM_PC_BC25,ADM_PC_BI25;
BO_TX_BU_ 2483486787 : User,ADM_PC_LL25,ADM_PC_BC25,ADM_PC_BI25;
BO_TX_BU_ 2483486788 : User,ADM_PC_LL25,ADM_PC_BC25,ADM_PC_BI25;
CM_ BO_ 2483519488  "Identification of the device";
CM_ BO_ 2483519489  "Git revision of the DSP firmware";
CM_ BO_ 2483519501  "Git revision of the bootloader firmware.";
CM_ BO_ 2483519490  "Values for debugging of HW/SW problems";
CM_ BO_ 2483519495  "Status bitfield";
CM_ BO_ 2483519494  "Fault bitfield";
CM_ BO_ 2483519491  "Current of phases U, V, W";
CM_ BO_ 2483519504  "Current of of the DC Bus";
CM_ BO_ 2483519502  "All AFEs will listen to this message";
CM_ BO_ 2483519499  "RMS Current of phases U, V, W";
CM_ BO_ 2483519500  "Three-Phase mains health (frequency, phase...)";
CM_ BO_ 2483519493  "Readouts of the module temperature sensors";
CM_ BO_ 2483519496  "Setpoints";
CM_ BO_ 2483519497  "Setpoints";
CM_ BO_ 2483486816  "Keep alive ping message. ";
CM_ BO_ 2483486784  "Operation Mode control: sets the converter operation mode";
CM_ BO_ 2483486800  "Fault Control: actions to clear faults and reset the system";
CM_ BO_ 2483486785  "Reactive power setpoint control.";
CM_ BO_ 2483486786  "PWM duty cycle control";
CM_ BO_ 2483486787  "Current setpoint control";
CM_ BO_ 2483486788  "Voltage setpoint control";
CM_ BO_ 2483486792  "Frequency setpoint control";
CM_ BO_ 2483486793  "Phase setpoint control";
CM_ BO_ 2483486832  "Additional voltage and current setpoints in single-phase rectifier and inverter control modes.";
CM_ BO_ 2483486789  "PFC stack control";
CM_ BO_ 2483486768  "Set the input and output voltage limits (minimum and maximum)";
CM_ BO_ 2483486769  "Set the output current limits (mminimum and maximum)";
CM_ BO_ 2483486796  "Set the Group ID of the device";
CM_ BO_ 2483519503  "Contains the Group ID of the device";
CM_ BO_ 2483486817  "Control the system flags";
CM_ BO_ 2483519520  "Current of phases A and B";
CM_ BO_ 2483519521  "Current of phases A and B";
CM_ BO_ 2483486794  "Automatic ADC calibration.";
CM_ BO_ 2483486795  "Setpoint for automatic ADC calibration.";
CM_ BO_ 2483486790  "Update of the calibration table for offsets.";
CM_ BO_ 2483486791  "Update of the calibration table for scales.";
CM_ BO_ 2483519569  "
                Adc scale (resolution) value of readouts.
            ";
CM_ BO_ 2483519570  "
                Adc fullscale value of readouts.
            ";
CM_ BO_ 2483519571  "
                Readout of ADC calibration data (offset) from EEPROM.
            ";
CM_ BO_ 2483519572  "
                Readout of ADC calibration data (gain) from EEPROM.
            ";
CM_ BO_ 2483519574  "Fault bitfield";

CM_ SG_ 2483519488 Device_type_20 "The device identification field, uniquely identifies the sender in the network";
CM_ SG_ 2483519488 HW_revision_20 "The hardware revision number";
CM_ SG_ 2483519488 HW_variant_20 "The DSP firmware revision number";
CM_ SG_ 2483519488 Stack_position_20 "Position of the module within the stack";
CM_ SG_ 2483519488 SN_number_20 "Unique module serial number";
CM_ SG_ 2483519489 FW_revision_0_20 "Character 0";
CM_ SG_ 2483519489 FW_revision_1_20 "Character 1";
CM_ SG_ 2483519489 FW_revision_2_20 "Character 2";
CM_ SG_ 2483519489 FW_revision_3_20 "Character 3";
CM_ SG_ 2483519489 FW_revision_4_20 "Character 3";
CM_ SG_ 2483519489 FW_revision_5_20 "Character 3";
CM_ SG_ 2483519489 FW_revision_6_20 "Character 3";
CM_ SG_ 2483519489 FW_revision_7_20 "Character 7";
CM_ SG_ 2483519489 FW_revision_8_20 "Character 8";
CM_ SG_ 2483519489 FW_revision_9_20 "Character 9";
CM_ SG_ 2483519489 FW_revision_10_20 "Character 10";
CM_ SG_ 2483519489 FW_revision_11_20 "Character 11";
CM_ SG_ 2483519489 FW_revision_12_20 "Character 12";
CM_ SG_ 2483519489 FW_revision_13_20 "Character 13";
CM_ SG_ 2483519489 FW_datecode_0_20 "Character 0";
CM_ SG_ 2483519489 FW_datecode_1_20 "Character 1";
CM_ SG_ 2483519489 FW_datecode_2_20 "Character 2";
CM_ SG_ 2483519489 FW_datecode_3_20 "Character 3";
CM_ SG_ 2483519489 FW_datecode_4_20 "Character 3";
CM_ SG_ 2483519489 FW_datecode_5_20 "Character 3";
CM_ SG_ 2483519489 FW_datecode_6_20 "Character 3";
CM_ SG_ 2483519489 FW_datecode_7_20 "Character 7";
CM_ SG_ 2483519489 FW_datecode_8_20 "Character 8";
CM_ SG_ 2483519489 FW_datecode_9_20 "Character 9";
CM_ SG_ 2483519489 FW_datecode_10_20 "Character 10";
CM_ SG_ 2483519489 FW_datecode_11_20 "Character 11";
CM_ SG_ 2483519489 FW_datecode_12_20 "Character 12";
CM_ SG_ 2483519489 FW_datecode_13_20 "Character 13";
CM_ SG_ 2483519501 FW_revision_0_20 "Character 0";
CM_ SG_ 2483519501 FW_revision_1_20 "Character 1";
CM_ SG_ 2483519501 FW_revision_2_20 "Character 2";
CM_ SG_ 2483519501 FW_revision_3_20 "Character 3";
CM_ SG_ 2483519501 FW_revision_4_20 "Character 3";
CM_ SG_ 2483519501 FW_revision_5_20 "Character 3";
CM_ SG_ 2483519501 FW_revision_6_20 "Character 3";
CM_ SG_ 2483519501 FW_revision_7_20 "Character 7";
CM_ SG_ 2483519501 FW_revision_8_20 "Character 8";
CM_ SG_ 2483519501 FW_revision_9_20 "Character 9";
CM_ SG_ 2483519501 FW_revision_10_20 "Character 10";
CM_ SG_ 2483519501 FW_revision_11_20 "Character 11";
CM_ SG_ 2483519501 FW_revision_12_20 "Character 12";
CM_ SG_ 2483519501 FW_revision_13_20 "Character 13";
CM_ SG_ 2483519501 FW_datecode_0_20 "Character 0";
CM_ SG_ 2483519501 FW_datecode_1_20 "Character 1";
CM_ SG_ 2483519501 FW_datecode_2_20 "Character 2";
CM_ SG_ 2483519501 FW_datecode_3_20 "Character 3";
CM_ SG_ 2483519501 FW_datecode_4_20 "Character 3";
CM_ SG_ 2483519501 FW_datecode_5_20 "Character 3";
CM_ SG_ 2483519501 FW_datecode_6_20 "Character 3";
CM_ SG_ 2483519501 FW_datecode_7_20 "Character 7";
CM_ SG_ 2483519501 FW_datecode_8_20 "Character 8";
CM_ SG_ 2483519501 FW_datecode_9_20 "Character 9";
CM_ SG_ 2483519501 FW_datecode_10_20 "Character 10";
CM_ SG_ 2483519501 FW_datecode_11_20 "Character 11";
CM_ SG_ 2483519501 FW_datecode_12_20 "Character 12";
CM_ SG_ 2483519501 FW_datecode_13_20 "Character 13";
CM_ SG_ 2483519490 Status_Error_Code_20 "Main status / error code as defined in errno/errno.h";
CM_ SG_ 2483519490 Data_1_20 "Additional information for the error/status";
CM_ SG_ 2483519490 Data_2_20 "Additional information for the error/status";
CM_ SG_ 2483519490 Data_3_20 "Additional information for the error/status";
CM_ SG_ 2483519495 Running_20 "Indicates if converter is running.";
CM_ SG_ 2483519495 PWM_20 "Indicates if converter is in PWM control mode.";
CM_ SG_ 2483519495 Current_dc_loop_mode_20 "Indicates if the current DC loop is enabled.";
CM_ SG_ 2483519495 Current_ac_loop_mode_20 "Indicates if the current AC loop is enabled.";
CM_ SG_ 2483519495 Buck_20 "Indicates if converter is in buck control mode.";
CM_ SG_ 2483519495 Boost_20 "Indicates if converter is in boost control mode.";
CM_ SG_ 2483519495 Precharge_dc_buck_mode_20 "Indicates if the precharge DC mode is enabled - buck direction.";
CM_ SG_ 2483519495 Precharge_dc_boost_mode_20 "Indicates if the precharge DC mode is enabled - boost direction.";
CM_ SG_ 2483519495 Rectifier_3ph_20 "Indicates if converter is in three-phase rectifier control mode.";
CM_ SG_ 2483519495 Stack_mode_20 "Indicates if converter is operating in stack mode.";
CM_ SG_ 2483519495 Master_20 "Indicates if converter is master in the stack.";
CM_ SG_ 2483519495 Slave_20 "Indicates if converter is slave in the stack.";
CM_ SG_ 2483519495 Inverter_1ph_20 "Indicates if converter is in single-phase inverter control mode.";
CM_ SG_ 2483519495 Boost_Neutral_20 "Indicates if converter is in boost control mode with neutral generation.";
CM_ SG_ 2483519495 Rectifier_1ph_20 "Indicates if converter is in single-phase rectifier control mode.";
CM_ SG_ 2483519495 Inverter_3ph_20 "Indicates if converter is in three-phase inverter control mode.";
CM_ SG_ 2483519495 Ready_20 "Indicates if converter is ready for operation.";
CM_ SG_ 2483519495 Inverter_1ph_Sync_20 "Single-phase inverter control mode with phase synchronization.";
CM_ SG_ 2483519495 Neutral_20 "Open-loop neutral generation.";
CM_ SG_ 2483519495 Rectifier_1ph_Buck_20 "Single-phase rectifier with buck on one leg.";
CM_ SG_ 2483519495 Inverter_1ph_Boost_20 "Single-phase inverter with boost on one leg.";
CM_ SG_ 2483519495 Rectifier_distributed_20 "Not available at the moment";
CM_ SG_ 2483519495 MPPT_buck_20 "Not available at the moment";
CM_ SG_ 2483519495 MPPT_boost_20 "Not available at the moment";
CM_ SG_ 2483519495 Buck_2p_float_20 "Buck in phases L1 and L2. Phase L3 is left floating (high impedance)";
CM_ SG_ 2483519495 Inverter_1ph_Distributed_20 "Single-phase inverter mode  distributed";
CM_ SG_ 2483519494 Protection_trip_internal_20 "This flagg is asserted if the interlock is open due to an internal fault condition (self-protection)";
CM_ SG_ 2483519494 Protection_trip_external_20 "This flag is asserted if the interlock is open due to an external condition received in the module.";
CM_ SG_ 2483519494 Phase_U_overcurrent_20 "Indicates an overcurrent event on Phase U. The overcurrent event is triggered when the measured phase current is over the programmed current limit.";
CM_ SG_ 2483519494 Phase_U_overvoltage_20 "Indicates an overvoltage event on Phase U. The overvoltage event is triggered when the measured phase voltage is over the programmed voltage limit.";
CM_ SG_ 2483519494 Phase_U_undervoltage_20 "Indicates an undervoltage event on Phase U. The overvoltage event is triggered when the measured phase voltage is over the programmed voltage limit.";
CM_ SG_ 2483519494 Phase_V_overvoltage_20 "Indicates an overvoltage event on Phase V. The overvoltage event is triggered when the measured phase voltage is over the programmed voltage limit.";
CM_ SG_ 2483519494 Phase_V_undervoltage_20 "Indicates an undervoltage event on Phase U. The overvoltage event is triggered when the measured phase voltage is over the programmed voltage limit.";
CM_ SG_ 2483519494 Phase_V_overcurrent_20 "Indicates an overcurrent event on Phase U. The overcurrent event is triggered when the measured phase current is over the programmed current limit.";
CM_ SG_ 2483519494 Phase_W_overvoltage_20 "Indicates an overvoltage event on Phase U. The overvoltage event is triggered when the measured phase voltage is over the programmed voltage limit.";
CM_ SG_ 2483519494 Phase_W_undervoltage_20 "Indicates an undervoltage event on Phase U. The overvoltage event is triggered when the measured phase voltage is over the programmed voltage limit.";
CM_ SG_ 2483519494 Phase_W_overcurrent_20 "Indicates an overcurrent event on Phase U. The overcurrent event is triggered when the measured phase current is over the programmed current limit.";
CM_ SG_ 2483519494 DC_undervoltage_20 "DC bus undervoltage condition. The undervoltage condition is asserted when the measured dc bus voltage is under the programmed voltage limit.";
CM_ SG_ 2483519494 DC_overvoltage_20 "DC bus overvoltage condition. The overvoltage condition is asserted when the measured dc bus voltage is over the programmed voltage limit.";
CM_ SG_ 2483519494 MOSFET_overtemperature_20 "This flag is asserted when the temperature of the MOSFET block is too high.";
CM_ SG_ 2483519494 Inductor_overtemperature_20 "This flag is asserted when the temperature of the inductor block is too high.";
CM_ SG_ 2483519494 Keep_Alive_not_served_20 "The Keep Alive feature is enabled but it was not served with the periodic message.";
CM_ SG_ 2483519494 PLL_not_locked_20 "Flag asserted when in rectifier modes, the PLL went out of lock condition";
CM_ SG_ 2483519494 Measurement_system_failure_20 "The voltages/currents measurement system is malfunctionning, and readouts are not guaranteed to be accurate.";
CM_ SG_ 2483519494 EEPROM_failure_20 "The configuration EEPROM failed to load or save the module configuration.";
CM_ SG_ 2483519491 Phase_U_20 "Phase current is the MOSFET loop current, in the branch U of the converter.";
CM_ SG_ 2483519491 Phase_V_20 "Phase current is the MOSFET loop current, in the branch V of the converter.";
CM_ SG_ 2483519491 Phase_W_20 "Phase current is the MOSFET loop current, in the branch W of the converter.";
CM_ SG_ 2483519504 Bus_current_20 "DC Bus current is possitive when current goes from input to output";
CM_ SG_ 2483519502 Phase_U_20 "Phase current is the MOSFET loop current, in the branch U of the converter.";
CM_ SG_ 2483519502 Phase_V_20 "Phase current is the MOSFET loop current, in the branch V of the converter.";
CM_ SG_ 2483519502 Phase_W_20 "Phase current is the MOSFET loop current, in the branch W of the converter.";
CM_ SG_ 2483519502 Stack_position_20 "Sender Stack position";
CM_ SG_ 2483519502 Group_ID_20 "Sender Group ID";
CM_ SG_ 2483519499 Phase_U_20 "RMS Phase current is the MOSFET loop current, in the branch U of the converter.";
CM_ SG_ 2483519499 Phase_V_20 "RMS Phase current is the MOSFET loop current, in the branch V of the converter.";
CM_ SG_ 2483519499 Phase_W_20 "RMS Phase current is the MOSFET loop current, in the branch W of the converter.";
CM_ SG_ 2483519500 Frequency_20 "Frequency of Three-Phase system";
CM_ SG_ 2483519500 Phase_20 "Phase of Three-Phase system";
CM_ SG_ 2483519493 Temp_Bridge_20 "Temperature of the MOSFET block";
CM_ SG_ 2483519493 Temp_Inductors_20 "Temperature of the inductors";
CM_ SG_ 2483519496 Phase_U_20 "The actual PWM duty cycle setpoint";
CM_ SG_ 2483519496 Phase_V_20 "The actual PWM duty cycle setpoint";
CM_ SG_ 2483519496 Phase_W_20 "The actual PWM duty cycle setpoint";
CM_ SG_ 2483519497 Current_setpoint_20 "The actual current setpoint";
CM_ SG_ 2483519497 Voltage_setpoint_20 "The actual voltage setpoint";
CM_ SG_ 2483519497 Frequency_setpoint_20 "The actual frequency setpoint";
CM_ SG_ 2483486816 Keep_Alive_Enable_20 "If set to 1, module will expect to receive this message every second repeatedly, or it will stop operation";
CM_ SG_ 2483486784 Converter_ON_20 "Enable the converter.";
CM_ SG_ 2483486784 PWM_ON_20 "Enable the PWM control mode.";
CM_ SG_ 2483486784 DC_Current_feedback_ON_20 "Enable the DC current loop";
CM_ SG_ 2483486784 AC_Current_feedback_ON_20 "Enable the AC current loop";
CM_ SG_ 2483486784 Buck_ON_20 "Enable the buck control mode.";
CM_ SG_ 2483486784 Boost_ON_20 "Enable the boost control mode.";
CM_ SG_ 2483486784 Rectifier_3ph_ON_20 "Enable the three-phase rectifier control mode.";
CM_ SG_ 2483486784 Inverter_1ph_ON_20 "Enable the single-phase inverter control mode.";
CM_ SG_ 2483486784 Rectifier_1ph_ON_20 "Enable the single-phase rectifier control mode.";
CM_ SG_ 2483486784 Boost_Neutral_ON_20 "Enable the boost control mode with neutral generation.";
CM_ SG_ 2483486784 Inverter_3ph_ON_20 "Enable the three-phase inverter control mode.";
CM_ SG_ 2483486784 Inverter_1ph_Sync_ON_20 "Single-phase inverter control mode with phase synchronization.";
CM_ SG_ 2483486784 Neutral_ON_20 "Open-loop neutral generation.";
CM_ SG_ 2483486784 Rectifier_1ph_Buck_ON_20 "Single-phase rectifier with buck on one leg.";
CM_ SG_ 2483486784 Inverter_1ph_Boost_ON_20 "Single-phase inverter with boost on one leg.";
CM_ SG_ 2483486784 Rectifier_Distributed_ON_20 "Single-phase (floating) distributed rectifier";
CM_ SG_ 2483486784 MPPT_buck_ON_20 "MPPT buck";
CM_ SG_ 2483486784 MPPT_boost_ON_20 "MPPT boost";
CM_ SG_ 2483486784 Buck_2p_float_ON_20 "Boost on L1 and L2. Floating L3 (high-impedance)";
CM_ SG_ 2483486784 Inverter_1ph_Distributed_ON_20 "Single-phase inverter mode distributed";
CM_ SG_ 2483486800 Clear_Interlock_20 "Clears the converter interlock";
CM_ SG_ 2483486800 Reset_Processor_20 "Reset the converter DSP";
CM_ SG_ 2483486800 Trip_Interlock_20 "Trip the inetrnal Interlock";
CM_ SG_ 2483486785 Reactive_current_setpoint_20 "This defines reactive current setpoint for 3-phase rectifier mode";
CM_ SG_ 2483486786 Phase_U_20 "The actual PWM duty cycle setpoint";
CM_ SG_ 2483486786 Phase_V_20 "The actual PWM duty cycle setpoint";
CM_ SG_ 2483486786 Phase_W_20 "The actual PWM duty cycle setpoint";
CM_ SG_ 2483486787 Current_setpoint_20 "Sets the output current setpoint. Active only when the current loop is enabled";
CM_ SG_ 2483486788 Voltage_setpoint_20 "Sets the output voltage setpoint. Active only when the voltage loop is enabled";
CM_ SG_ 2483486792 Frequency_setpoint_20 "Sets the frequency for single-phase and three-phase generator modes.";
CM_ SG_ 2483486793 Phase_setpoint_20 "Sets the phase for inverter control modes.";
CM_ SG_ 2483486789 Stack_position_20 "The converter position within the stack";
CM_ SG_ 2483486789 Stack_size_20 "How many PFC converters are in stack in total";
CM_ SG_ 2483486789 SN_number_20 "Unique module serial number";
CM_ SG_ 2483486768 Phase_voltage_min_20 "Minimum tolerated phase voltage";
CM_ SG_ 2483486768 Phase_voltage_max_20 "Maximum allowable phase voltage";
CM_ SG_ 2483486768 DC_voltage_min_20 "Minimum allowable dc voltage";
CM_ SG_ 2483486768 DC_voltage_max_20 "Maximum allowable dc voltage";
CM_ SG_ 2483486769 Phase_current_min_20 "Minimum allowable output current";
CM_ SG_ 2483486769 Phase_current_max_20 "Maximum allowable output current";
CM_ SG_ 2483486796 Group_ID_20 "Desired group ID for the device";
CM_ SG_ 2483519503 Group_ID_20 "Group ID of the device";
CM_ SG_ 2483486817 Factory_mode_20 "Customers MUST NOT USE this bit. If set to 1, module will enter in factory mode. ";
CM_ SG_ 2483486817 Silent_CAN_mode_20 "Customers MUST NOT USE this bit. If set to 1, module will enter in factory mode. ";
CM_ SG_ 2483486794 start_20 "Start automatic calibration. Multiplexer index must be 0!";
CM_ SG_ 2483486795 point_20 "Calibration point index.";
CM_ SG_ 2483486790 CRC_20 "Checksum of bytes 0 to 3, CRC-CCITT, corresponding to qChecksum (www.qt.io)";
CM_ SG_ 2483486791 CRC_20 "Checksum of bytes 0 to 3, CRC-CCITT, corresponding to qChecksum (www.qt.io)";
CM_ SG_ 2483519574 Current_U_High_20 "This flag is set if a hight current on U tripped the internal interlock";
CM_ SG_ 2483519574 Current_U_Low_20 "This flag is set if a low current on U tripped the internal interlock";
CM_ SG_ 2483519574 Current_V_High_20 "This flag is set if a hight current on V tripped the internal interlock";
CM_ SG_ 2483519574 Current_V_Low_20 "This flag is set if a low current on V tripped the internal interlock";
CM_ SG_ 2483519574 Current_W_High_20 "This flag is set if a hight current on W tripped the internal interlock";
CM_ SG_ 2483519574 Current_W_Low_20 "This flag is set if a low current on W tripped the internal interlock";
CM_ SG_ 2483519574 Voltage_DC_20 "This flag is set if a voltage on DC tripped the internal interlock";
CM_ SG_ 2483519574 Reboot_20 "This flag is set if a reboot tripped the internal interlock";
CM_ SG_ 2483519574 Unknown_20 "This flag the reason for the internal interlock is unknown";

BA_DEF_ BO_ "SystemMessageLongSymbol" STRING;

BA_ "SystemMessageLongSymbol" BO_ 2483486785 "AFE_Reactive_Current_Setpoint_Control_20";
BA_ "SystemMessageLongSymbol" BO_ 2483486792 "AFE_Frequency_Setpoint_Control_20";
BA_ "SystemMessageLongSymbol" BO_ 2483486832 "AFE_Rectifier_Setpoint_Control_20";
BA_ "SystemMessageLongSymbol" BO_ 2483486790 "_AFE_Calibration_Offset_Update_20";

VAL_ 2483519488 Device_type_20 7 "AFE";
VAL_ 2483519494 Protection_trip_internal_20 1 "fault";
VAL_ 2483519494 Protection_trip_external_20 1 "fault";
VAL_ 2483519494 Phase_U_overcurrent_20 1 "fault";
VAL_ 2483519494 Phase_U_overvoltage_20 1 "fault";
VAL_ 2483519494 Phase_U_undervoltage_20 1 "fault";
VAL_ 2483519494 Phase_V_overvoltage_20 1 "fault";
VAL_ 2483519494 Phase_V_undervoltage_20 1 "fault";
VAL_ 2483519494 Phase_V_overcurrent_20 1 "fault";
VAL_ 2483519494 Phase_W_overvoltage_20 1 "fault";
VAL_ 2483519494 Phase_W_undervoltage_20 1 "fault";
VAL_ 2483519494 Phase_W_overcurrent_20 1 "fault";
VAL_ 2483519494 DC_undervoltage_20 1 "fault";
VAL_ 2483519494 DC_overvoltage_20 1 "fault";
VAL_ 2483519494 MOSFET_overtemperature_20 1 "fault";
VAL_ 2483519494 Inductor_overtemperature_20 1 "fault";
VAL_ 2483519494 Keep_Alive_not_served_20 1 "fault";
VAL_ 2483519494 PLL_not_locked_20 1 "fault";
VAL_ 2483519494 NFO_20 1 "fault";
VAL_ 2483519494 Measurement_system_failure_20 1 "fault";
VAL_ 2483519494 EEPROM_failure_20 1 "fault";
VAL_ 2483519494 System_20 1 "fault";
VAL_ 2483519574 Current_U_High_20 1 "fault";
VAL_ 2483519574 Current_U_Low_20 1 "fault";
VAL_ 2483519574 Current_V_High_20 1 "fault";
VAL_ 2483519574 Current_V_Low_20 1 "fault";
VAL_ 2483519574 Current_W_High_20 1 "fault";
VAL_ 2483519574 Current_W_Low_20 1 "fault";
VAL_ 2483519574 Voltage_DC_20 1 "fault";
VAL_ 2483519574 Reboot_20 1 "fault";
VAL_ 2483519574 Unknown_20 1 "fault";
SIG_VALTYPE_ 2483519569 Current_U_20 : 1;
SIG_VALTYPE_ 2483519569 Current_V_20 : 1;
SIG_VALTYPE_ 2483519569 Current_W_20 : 1;
SIG_VALTYPE_ 2483519569 Voltage_U_20 : 1;
SIG_VALTYPE_ 2483519569 Voltage_V_20 : 1;
SIG_VALTYPE_ 2483519569 Voltage_W_20 : 1;
SIG_VALTYPE_ 2483519569 Voltage_DC_20 : 1;
SIG_VALTYPE_ 2483519570 Current_U_20 : 1;
SIG_VALTYPE_ 2483519570 Current_V_20 : 1;
SIG_VALTYPE_ 2483519570 Current_W_20 : 1;
SIG_VALTYPE_ 2483519570 Voltage_U_20 : 1;
SIG_VALTYPE_ 2483519570 Voltage_V_20 : 1;
SIG_VALTYPE_ 2483519570 Voltage_W_20 : 1;
SIG_VALTYPE_ 2483519570 Voltage_DC_20 : 1;
